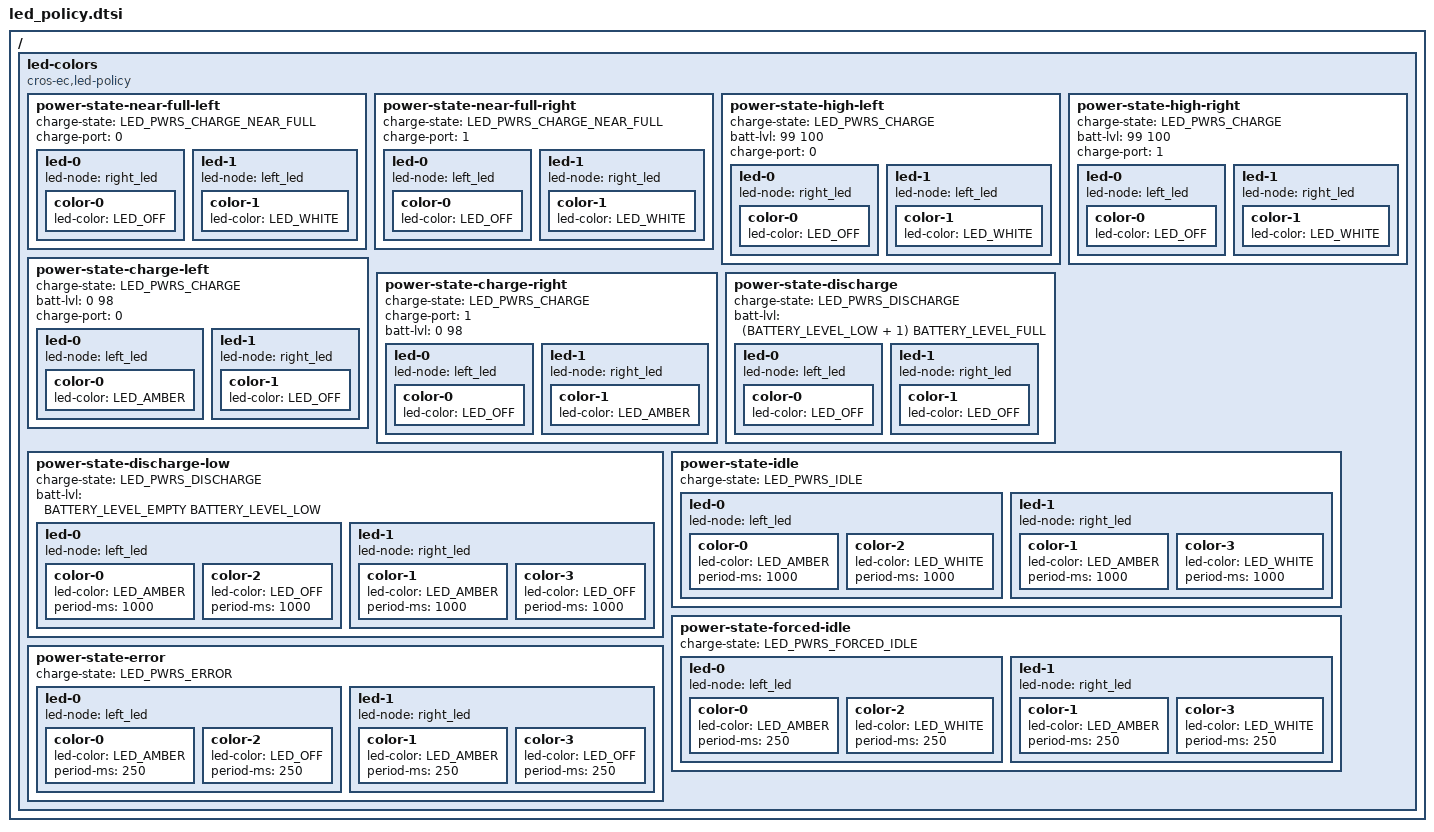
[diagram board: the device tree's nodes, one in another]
#include <dt-bindings/battery.h>

/ {
	led-colors {
		compatible = "cros-ec,led-policy";

		power-state-near-full-left {
			charge-state = "LED_PWRS_CHARGE_NEAR_FULL";
			charge-port = <0>; /* Left port */

			led-0 {
				led-node=<&right_led>;
				/* Turn off the right LED */
				color-0 {
					led-color = "LED_OFF";
				};
			};

			led-1 {
				led-node=<&left_led>;
				/* Left LED to White */
				color-1 {
					led-color = "LED_WHITE";
				};
			};
		};

		power-state-near-full-right {
			charge-state = "LED_PWRS_CHARGE_NEAR_FULL";
			charge-port = <1>; /* Right port */

			led-0 {
				led-node=<&left_led>;

				/* Turn off the left LED */
				color-0 {
					led-color = "LED_OFF";
				};
			};

			led-1 {
				led-node=<&right_led>;
				/* Right LED to White */
				color-1 {
					led-color = "LED_WHITE";
				};
			};
		};

		power-state-high-left {
			charge-state = "LED_PWRS_CHARGE";
			/* Battery percent range 99..100 */
			batt-lvl = <99 100>;

			charge-port = <0>; /* Left port */

			led-0 {
				led-node=<&right_led>;

				/* Turn off the right LED */
				color-0 {
					led-color = "LED_OFF";
				};
			};

			led-1 {
				led-node=<&left_led>;
				/* Left LED to White */
				color-1 {
					led-color = "LED_WHITE";
				};
			};
		};

		power-state-high-right {
			charge-state = "LED_PWRS_CHARGE";
			/* Battery percent range 99..100 */
			batt-lvl = <99 100>;
			charge-port = <1>; /* Right port */

			led-0 {
				led-node=<&left_led>;

				/* Turn off the left LED */
				color-0 {
					led-color = "LED_OFF";
				};
			};

			led-1 {
				led-node=<&right_led>;
				/* Right LED to White */
				color-1 {
					led-color = "LED_WHITE";
				};
			};
		};

		power-state-charge-left {
			charge-state = "LED_PWRS_CHARGE";
			/* Battery percent range 0..98 */
			batt-lvl = <0 98>;
			charge-port = <0>; /* Left port */

			led-0 {
				led-node=<&left_led>;

				/* Left LED to Amber */
				color-0 {
					led-color = "LED_AMBER";
				};
			};

			led-1 {
				led-node=<&right_led>;
				/* Turn off the right LED */
				color-1 {
					led-color = "LED_OFF";
				};
			};
		};

		power-state-charge-right {
			charge-state = "LED_PWRS_CHARGE";
			charge-port = <1>; /* Right port */
			/* Battery percent range 0..98 */
			batt-lvl = <0 98>;

			led-0 {
				led-node=<&left_led>;

				/* Turn off the left LED */
				color-0 {
					led-color = "LED_OFF";
				};
			};

			led-1 {
				led-node=<&right_led>;
				/* Right LED to Amber */
				color-1 {
					led-color = "LED_AMBER";
				};
			};
		};

		power-state-discharge {
			charge-state = "LED_PWRS_DISCHARGE";
			/* Battery percent range (> Low, <= Full) */
			batt-lvl = <(BATTERY_LEVEL_LOW + 1) BATTERY_LEVEL_FULL>;

			led-0 {
				led-node=<&left_led>;

				/* Turn off both LEDs LED */
				color-0 {
					led-color = "LED_OFF";
				};
			};

			led-1 {
				led-node=<&right_led>;
				color-1 {
					led-color = "LED_OFF";
				};
			};
		};

		power-state-discharge-low {
			charge-state = "LED_PWRS_DISCHARGE";
			/* Battery percent range (>= Empty, <= Low) */
			batt-lvl = <BATTERY_LEVEL_EMPTY BATTERY_LEVEL_LOW>;

			led-0 {
				led-node=<&left_led>;

				/* Blink both LEDs amber at 0.5 Hz */
				color-0 {
					led-color = "LED_AMBER";
					period-ms = <1000>;
				};
				color-2 {
					led-color = "LED_OFF";
					period-ms = <1000>;
				};
			};

			led-1 {
				led-node=<&right_led>;
				color-1 {
					led-color = "LED_AMBER";
					period-ms = <1000>;
				};
				color-3 {
					led-color = "LED_OFF";
					period-ms = <1000>;
				};
			};
		};

		power-state-idle {
			charge-state = "LED_PWRS_IDLE";

			led-0 {
				led-node=<&left_led>;

				/* Blink both LEDs amber at 0.5 Hz */
				color-0 {
					led-color = "LED_AMBER";
					period-ms = <1000>;
				};
				color-2 {
					led-color = "LED_WHITE";
					period-ms = <1000>;
				};
			};

			led-1 {
				led-node=<&right_led>;
				color-1 {
					led-color = "LED_AMBER";
					period-ms = <1000>;
				};
				color-3 {
					led-color = "LED_WHITE";
					period-ms = <1000>;
				};
			};
		};

		power-state-forced-idle {
			charge-state = "LED_PWRS_FORCED_IDLE";

			led-0 {
				led-node=<&left_led>;

				/* Blink both LEDs amber at 2 Hz */
				color-0 {
					led-color = "LED_AMBER";
					period-ms = <250>;
				};
				color-2 {
					led-color = "LED_WHITE";
					period-ms = <250>;
				};
			};

			led-1 {
				led-node=<&right_led>;
				color-1 {
					led-color = "LED_AMBER";
					period-ms = <250>;
				};
				color-3 {
					led-color = "LED_WHITE";
					period-ms = <250>;
				};
			};
		};

		power-state-error {
			charge-state = "LED_PWRS_ERROR";

			led-0 {
				led-node=<&left_led>;

				/* Blink both LEDs amber at 2 Hz */
				color-0 {
					led-color = "LED_AMBER";
					period-ms = <250>;
				};
				color-2 {
					led-color = "LED_OFF";
					period-ms = <250>;
				};
			};

			led-1 {
				led-node=<&right_led>;
				color-1 {
					led-color = "LED_AMBER";
					period-ms = <250>;
				};
				color-3 {
					led-color = "LED_OFF";
					period-ms = <250>;
				};
			};
		};

	};
};
